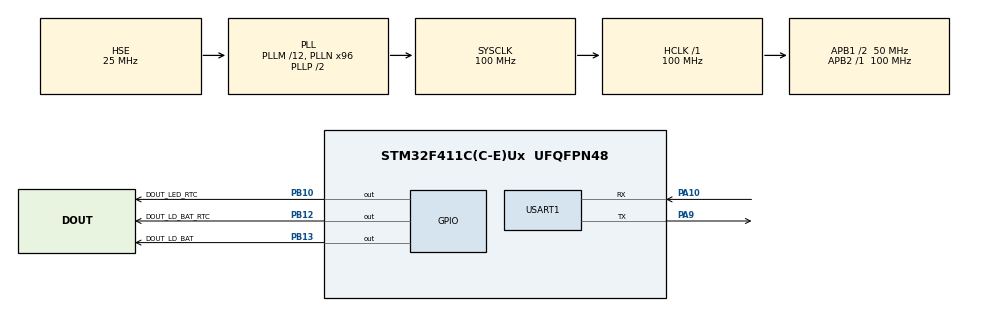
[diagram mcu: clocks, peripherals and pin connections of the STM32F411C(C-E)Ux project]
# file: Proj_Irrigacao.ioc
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FREERTOS.Tasks01=defaultTask,24,128,StartDefaultTask,Default,NULL,Dynamic,NULL,NULL
FREERTOS.configUSE_NEWLIB_REENTRANT=1
Mcu.Family=STM32F4
Mcu.Name=STM32F411C(C-E)Ux
Mcu.Package=UFQFPN48
NVIC.PriorityGroup=NVIC_PRIORITYGROUP_4
NVIC.RTC_Alarm_IRQn=true\:5\:0\:false\:false\:true\:true\:true\:true
NVIC.TIM1_TRG_COM_TIM11_IRQn=true\:15\:0\:false\:false\:true\:false\:false\:true
NVIC.TimeBase=TIM1_TRG_COM_TIM11_IRQn
NVIC.TimeBaseIP=TIM11
PA10.Mode=Asynchronous
PA10.Signal=USART1_RX
PA13.Mode=Serial_Wire
PA13.Signal=SYS_JTMS-SWDIO
PA14.Mode=Serial_Wire
PA14.Signal=SYS_JTCK-SWCLK
PA9.Mode=Asynchronous
PA9.Signal=USART1_TX
PB10.GPIO_Label=DOUT_LED_RTC
PB10.Signal=GPIO_Output
PB12.GPIO_Label=DOUT_LD_BAT_RTC
PB12.Signal=GPIO_Output
PB13.GPIO_Label=DOUT_LD_BAT
PB13.Signal=GPIO_Output
PC14-OSC32_IN.Mode=LSE-External-Oscillator
PC14-OSC32_IN.Signal=RCC_OSC32_IN
PC15-OSC32_OUT.Mode=LSE-External-Oscillator
PC15-OSC32_OUT.Signal=RCC_OSC32_OUT
PH0\ -\ OSC_IN.Mode=HSE-External-Oscillator
PH0\ -\ OSC_IN.Signal=RCC_OSC_IN
PH1\ -\ OSC_OUT.Mode=HSE-External-Oscillator
PH1\ -\ OSC_OUT.Signal=RCC_OSC_OUT
ProjectManager.HeapSize=0x200
ProjectManager.StackSize=0x400
ProjectManager.TargetToolchain=STM32CubeIDE
RCC.48MHZClocksFreq_Value=50000000
RCC.AHBFreq_Value=100000000
RCC.APB1CLKDivider=RCC_HCLK_DIV2
RCC.APB1Freq_Value=50000000
RCC.APB1TimFreq_Value=100000000
RCC.APB2Freq_Value=100000000
RCC.APB2TimFreq_Value=100000000
RCC.CortexFreq_Value=100000000
RCC.HCLKFreq_Value=100000000
RCC.HSE_VALUE=25000000
RCC.HSI_VALUE=16000000
RCC.PLLM=12
RCC.PLLN=96
RCC.PLLSourceVirtual=RCC_PLLSOURCE_HSE
RCC.RCC_RTC_Clock_Source=RCC_RTCCLKSOURCE_LSE
RCC.SYSCLKFreq_VALUE=100000000
RCC.SYSCLKSource=RCC_SYSCLKSOURCE_PLLCLK
RCC.VCOOutputFreq_Value=200000000
RTC.Alarm=RTC_ALARM_A
USART1.VirtualMode=VM_ASYNC
VP_FREERTOS_VS_CMSIS_V2.Mode=CMSIS_V2
VP_RTC_VS_RTC_Activate.Mode=RTC_Enabled
VP_RTC_VS_RTC_Alarm_A_Intern.Mode=Alarm A
VP_RTC_VS_RTC_Calendar.Mode=RTC_Calendar
VP_SYS_VS_tim11.Mode=TIM11
board=custom

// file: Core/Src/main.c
/* USER CODE BEGIN Header */
/**
  ******************************************************************************
  * @file           : main.c
  * @brief          : Main program body
  ******************************************************************************
  * @attention
  *
  * <h2><center>&copy; Copyright (c) 2022 STMicroelectronics.
  * All rights reserved.</center></h2>
  *
  * This software component is licensed by ST under BSD 3-Clause license,
  * the "License"; You may not use this file except in compliance with the
  * License. You may obtain a copy of the License at:
  *                        opensource.org/licenses/BSD-3-Clause
  *
  ******************************************************************************
  */
/* USER CODE END Header */
#include "main.h"

/* USER CODE BEGIN Includes */
#include "FreeRTOS.h"
#include "task.h"
#include "queue.h"
#include "semphr.h"

#include "rtc.h"
#include "serial.h"

#include "sys_eventgroup.h"

/* USER CODE END Includes */

RTC_HandleTypeDef hrtc;

UART_HandleTypeDef huart1;

/* Definitions for defaultTask */

void SystemClock_Config(void);
static void MX_GPIO_Init(void);
static void MX_USART1_UART_Init(void);
static void MX_RTC_Init(void);

int main(void)
{

  /* MCU Configuration--------------------------------------------------------*/

  /* Reset of all peripherals, Initializes the Flash interface and the Systick. */
  HAL_Init();

  /* Configure the system clock */
  SystemClock_Config();

  /* Initialize all configured peripherals */
  MX_GPIO_Init();
  MX_USART1_UART_Init();
  MX_RTC_Init();

  /* Init scheduler */

  /* USER CODE BEGIN RTOS_QUEUES */

  /**
   * @author: cria queue de requisição de dados do rtc
   */
  vRTC_CreateQueueRTCRequest();
  /* add queues, ... */

  /* USER CODE END RTOS_QUEUES */

  /* Create the thread(s) */
  /* creation of defaultTask */

  /* USER CODE BEGIN RTOS_THREADS */
  /* add threads, ... */

  /*INICIALIZAÇÃO DE TASK LED RTC DEBUG --- OK*/
  // vRTC_CreateTaskLed();
  /*INICIALIZAÇÃO DE TASK CheckRTC DEBUG*/
//  vRTC_CreateTaskCheckRTC();

  /* USER CODE END RTOS_THREADS */

  /* USER CODE BEGIN RTOS_EVENTS */
  /* add events, ... */

  /**
   * @author: event group geral do sistema
   */
//  vRTC_CreateEventgroups();
  vSYSEVENTGROUP_CreateEventgroups();
  /* USER CODE END RTOS_EVENTS */

  /* Start scheduler */

  /* We should never get here as control is now taken by the scheduler */
  /* Infinite loop */
  /* USER CODE BEGIN WHILE */

  /**
   * @author inicializacao de tasks
   */
  vRTC_CreateTaskCheckRTC();
  vRTC_CreateTaskConfigRTC();

  vTaskStartScheduler();
  while (1)
  {
    /* USER CODE END WHILE */

  }
}

void SystemClock_Config(void)
{
  RCC_OscInitTypeDef RCC_OscInitStruct = {0};
  RCC_ClkInitTypeDef RCC_ClkInitStruct = {0};

  /** Configure the main internal regulator output voltage
  */
  __HAL_RCC_PWR_CLK_ENABLE();
  __HAL_PWR_VOLTAGESCALING_CONFIG(PWR_REGULATOR_VOLTAGE_SCALE1);
  /** Initializes the RCC Oscillators according to the specified parameters
  * in the RCC_OscInitTypeDef structure.
  */
  RCC_OscInitStruct.OscillatorType = RCC_OSCILLATORTYPE_HSE|RCC_OSCILLATORTYPE_LSE;
  RCC_OscInitStruct.HSEState = RCC_HSE_ON;
  RCC_OscInitStruct.LSEState = RCC_LSE_ON;
  RCC_OscInitStruct.PLL.PLLState = RCC_PLL_ON;
  RCC_OscInitStruct.PLL.PLLSource = RCC_PLLSOURCE_HSE;
  RCC_OscInitStruct.PLL.PLLM = 12;
  RCC_OscInitStruct.PLL.PLLN = 96;
  RCC_OscInitStruct.PLL.PLLP = RCC_PLLP_DIV2;
  RCC_OscInitStruct.PLL.PLLQ = 4;
  if (HAL_RCC_OscConfig(&RCC_OscInitStruct) != HAL_OK)
  {
    Error_Handler();
  }
  /** Initializes the CPU, AHB and APB buses clocks
  */
  RCC_ClkInitStruct.ClockType = RCC_CLOCKTYPE_HCLK|RCC_CLOCKTYPE_SYSCLK
                              |RCC_CLOCKTYPE_PCLK1|RCC_CLOCKTYPE_PCLK2;
  RCC_ClkInitStruct.SYSCLKSource = RCC_SYSCLKSOURCE_PLLCLK;
  RCC_ClkInitStruct.AHBCLKDivider = RCC_SYSCLK_DIV1;
  RCC_ClkInitStruct.APB1CLKDivider = RCC_HCLK_DIV2;
  RCC_ClkInitStruct.APB2CLKDivider = RCC_HCLK_DIV1;

  if (HAL_RCC_ClockConfig(&RCC_ClkInitStruct, FLASH_LATENCY_3) != HAL_OK)
  {
    Error_Handler();
  }
}

static void MX_RTC_Init(void)
{

  RTC_TimeTypeDef sTime = {0};
  RTC_DateTypeDef sDate = {0};
  RTC_AlarmTypeDef sAlarm = {0};

  /** Initialize RTC Only
  */
  hrtc.Instance = RTC;
  hrtc.Init.HourFormat = RTC_HOURFORMAT_24;
  hrtc.Init.AsynchPrediv = 127;
  hrtc.Init.SynchPrediv = 255;
  hrtc.Init.OutPut = RTC_OUTPUT_DISABLE;
  hrtc.Init.OutPutPolarity = RTC_OUTPUT_POLARITY_HIGH;
  hrtc.Init.OutPutType = RTC_OUTPUT_TYPE_OPENDRAIN;
  if (HAL_RTC_Init(&hrtc) != HAL_OK)
  {
    Error_Handler();
  }

  /** Initialize RTC and set the Time and Date
  */
  sTime.Hours = 0x0;
  sTime.Minutes = 0x0;
  sTime.Seconds = 0x0;
  sTime.DayLightSaving = RTC_DAYLIGHTSAVING_NONE;
  sTime.StoreOperation = RTC_STOREOPERATION_RESET;
  if (HAL_RTC_SetTime(&hrtc, &sTime, RTC_FORMAT_BCD) != HAL_OK)
  {
    Error_Handler();
  }
  sDate.WeekDay = RTC_WEEKDAY_MONDAY;
  sDate.Month = RTC_MONTH_JANUARY;
  sDate.Date = 0x1;
  sDate.Year = 0x0;

  if (HAL_RTC_SetDate(&hrtc, &sDate, RTC_FORMAT_BCD) != HAL_OK)
  {
    Error_Handler();
  }
  /** Enable the Alarm A
  */
  sAlarm.AlarmTime.Hours = 0x0;
  sAlarm.AlarmTime.Minutes = 0x0;
  sAlarm.AlarmTime.Seconds = 0x0;
  sAlarm.AlarmTime.SubSeconds = 0x0;
  sAlarm.AlarmTime.DayLightSaving = RTC_DAYLIGHTSAVING_NONE;
  sAlarm.AlarmTime.StoreOperation = RTC_STOREOPERATION_RESET;
  sAlarm.AlarmMask = RTC_ALARMMASK_NONE;
  sAlarm.AlarmSubSecondMask = RTC_ALARMSUBSECONDMASK_ALL;
  sAlarm.AlarmDateWeekDaySel = RTC_ALARMDATEWEEKDAYSEL_DATE;
  sAlarm.AlarmDateWeekDay = 0x1;
  sAlarm.Alarm = RTC_ALARM_A;
  if (HAL_RTC_SetAlarm_IT(&hrtc, &sAlarm, RTC_FORMAT_BCD) != HAL_OK)
  {
    Error_Handler();
  }

}

static void MX_USART1_UART_Init(void)
{

  huart1.Instance = USART1;
  huart1.Init.BaudRate = 115200;
  huart1.Init.WordLength = UART_WORDLENGTH_8B;
  huart1.Init.StopBits = UART_STOPBITS_1;
  huart1.Init.Parity = UART_PARITY_NONE;
  huart1.Init.Mode = UART_MODE_TX_RX;
  huart1.Init.HwFlowCtl = UART_HWCONTROL_NONE;
  huart1.Init.OverSampling = UART_OVERSAMPLING_16;
  if (HAL_UART_Init(&huart1) != HAL_OK)
  {
    Error_Handler();
  }

}

static void MX_GPIO_Init(void)
{
  GPIO_InitTypeDef GPIO_InitStruct = {0};

  /* GPIO Ports Clock Enable */
  __HAL_RCC_GPIOC_CLK_ENABLE();
  __HAL_RCC_GPIOH_CLK_ENABLE();
  __HAL_RCC_GPIOB_CLK_ENABLE();
  __HAL_RCC_GPIOA_CLK_ENABLE();

  /*Configure GPIO pin Output Level */
  HAL_GPIO_WritePin(GPIOB, DOUT_LED_RTC_Pin|DOUT_LD_BAT_RTC_Pin|DOUT_LD_BAT_Pin, GPIO_PIN_RESET);

  /*Configure GPIO pins : DOUT_LED_RTC_Pin DOUT_LD_BAT_RTC_Pin DOUT_LD_BAT_Pin */
  GPIO_InitStruct.Pin = DOUT_LED_RTC_Pin|DOUT_LD_BAT_RTC_Pin|DOUT_LD_BAT_Pin;
  GPIO_InitStruct.Mode = GPIO_MODE_OUTPUT_PP;
  GPIO_InitStruct.Pull = GPIO_NOPULL;
  GPIO_InitStruct.Speed = GPIO_SPEED_FREQ_LOW;
  HAL_GPIO_Init(GPIOB, &GPIO_InitStruct);

}

void HAL_TIM_PeriodElapsedCallback(TIM_HandleTypeDef *htim)
{
  if (htim->Instance == TIM11) {
    HAL_IncTick();
  }
}

void Error_Handler(void)
{
  __disable_irq();
  while (1)
  {
  }
}

/************************ (C) COPYRIGHT STMicroelectronics *****END OF FILE****/
